AUTOSAR XML (schema 00051)
package /Components
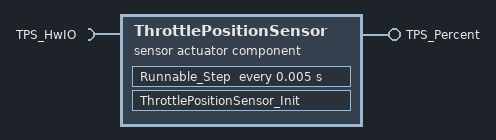
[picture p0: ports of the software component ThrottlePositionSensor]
  sensor actuator sw component type ThrottlePositionSensor
    require port TPS_HwIO: nonqueued-receiver-com-spec{data-element=Value, init-value=ComSpec609627c4_2b672c39cbb4038e:0}, required-interface=TPS_HwIO
    provide port TPS_Percent: nonqueued-sender-com-spec{data-element=Value, init-value=ComSpece8cc0683_087c2a38b9bc9a1e:0}, provided-interface=TPS_Percent
    behavior ThrottlePositionSensor_InternalBehavior: data-type-mapping=ThrottlePositionSensorDataTypeMappingsSet, handle-termination-and-restart=NO-SUPPORT, supports-multiple-instantiation=true
      timing event Event_Runnable_Step: start-on-event=Runnable_Step, period=0.005
      init event ThrottlePositionSensor_InitEvent: start-on-event=ThrottlePositionSensor_Init
      per-instance-parameters:
        parameter data prototype TPSPercent_LkupTbl: category=CURVE, sw-calibration-access=READ-WRITE, type=Appl_TPSPercent_LkupTbl, init-value=constant-reference={short-label=TPSPercent_LkupTbl, constant=TPSPercent_LkupTbl}
      runnable Runnable_Step
        data-read-access:
          access IN_TPS_HwIO_Value: accessed-variable=TPS_HwIO.Value
        data-write-access:
          access OUT_TPS_Percent_Value: accessed-variable=TPS_Percent.Value
        parameter access PICALPRM_TPSPercent_LkupTbl: accessed-parameter=TPSPercent_LkupTbl
      runnable ThrottlePositionSensor_Init
